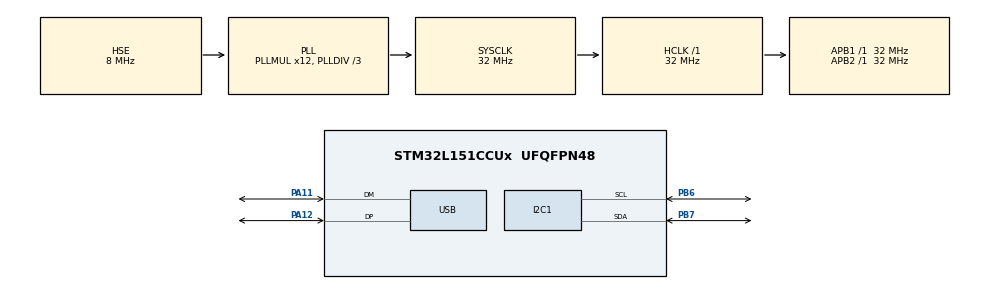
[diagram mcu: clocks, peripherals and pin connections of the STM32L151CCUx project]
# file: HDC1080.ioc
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Mcu.Family=STM32L1
Mcu.Name=STM32L151CCUx
Mcu.Package=UFQFPN48
NVIC.PriorityGroup=NVIC_PRIORITYGROUP_4
NVIC.USB_LP_IRQn=true\:0\:0\:false\:false\:true\:false\:true
PA11.Mode=Device
PA11.Signal=USB_DM
PA12.Mode=Device
PA12.Signal=USB_DP
PA13.Mode=Serial_Wire
PA13.Signal=SYS_JTMS-SWDIO
PA14.Mode=Serial_Wire
PA14.Signal=SYS_JTCK-SWCLK
PB6.Mode=I2C
PB6.Signal=I2C1_SCL
PB7.Mode=I2C
PB7.Signal=I2C1_SDA
PC14-OSC32_IN.Mode=LSE-External-Oscillator
PC14-OSC32_IN.Signal=RCC_OSC32_IN
PC15-OSC32_OUT.Mode=LSE-External-Oscillator
PC15-OSC32_OUT.Signal=RCC_OSC32_OUT
PH0-OSC_IN.Mode=HSE-External-Oscillator
PH0-OSC_IN.Signal=RCC_OSC_IN
PH1-OSC_OUT.Mode=HSE-External-Oscillator
PH1-OSC_OUT.Signal=RCC_OSC_OUT
ProjectManager.HeapSize=0x400
ProjectManager.StackSize=0x800
ProjectManager.TargetToolchain=MDK-ARM V5.27
RCC.48MHZClocksFreq_Value=48000000
RCC.AHBFreq_Value=32000000
RCC.APB1Freq_Value=32000000
RCC.APB1TimFreq_Value=32000000
RCC.APB2Freq_Value=32000000
RCC.APB2TimFreq_Value=32000000
RCC.HCLKFreq_Value=32000000
RCC.HSE_VALUE=8000000
RCC.HSI_VALUE=16000000
RCC.MSI_VALUE=2097000
RCC.PLLDIV=RCC_PLL_DIV3
RCC.PLLMUL=RCC_PLL_MUL12
RCC.SYSCLKFreq_VALUE=32000000
RCC.SYSCLKSource=RCC_SYSCLKSOURCE_PLLCLK
RCC.VCOOutputFreq_Value=96000000
USB_DEVICE.CLASS_NAME_FS=CDC
USB_DEVICE.VirtualMode=Cdc
USB_DEVICE.VirtualModeFS=Cdc_FS
VP_USB_DEVICE_VS_USB_DEVICE_CDC_FS.Mode=CDC_FS
board=custom

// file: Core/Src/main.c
/* USER CODE BEGIN Header */
/**
  ******************************************************************************
  * @file           : main.c
  * @brief          : Main program body
  ******************************************************************************
  * @attention
  *
  * <h2><center>&copy; Copyright (c) 2021 STMicroelectronics.
  * All rights reserved.</center></h2>
  *
  * This software component is licensed by ST under Ultimate Liberty license
  * SLA0044, the "License"; You may not use this file except in compliance with
  * the License. You may obtain a copy of the License at:
  *                             www.st.com/SLA0044
  *
  ******************************************************************************
  */
/* USER CODE END Header */
#include "main.h"
#include "i2c.h"
#include "usb_device.h"
#include "gpio.h"

/* USER CODE BEGIN Includes */
#include "usbd_cdc_if.h"
#include "HDC1080.h"
/* USER CODE END Includes */

void SystemClock_Config(void);

int main(void)
{

  /* MCU Configuration--------------------------------------------------------*/

  /* Reset of all peripherals, Initializes the Flash interface and the Systick. */
  HAL_Init();

  /* USER CODE BEGIN Init */
	uint16_t menuid;
	double temperature =0;

  /* USER CODE END Init */

  /* Configure the system clock */
  SystemClock_Config();

  /* Initialize all configured peripherals */
  MX_GPIO_Init();
  MX_USB_DEVICE_Init();
  MX_I2C1_Init();
  /* USER CODE BEGIN 2 */
	hdc1080_init(HDC1080_RESOLUTION_14BIT, HDC1080_RESOLUTION_14BIT);

  /* USER CODE END 2 */

  /* Infinite loop */
  while (1)
  {

    /* USER CODE BEGIN 3 */
		HAL_Delay(500);

	hdc1080_read_manufacturer_id(&menuid);
	hdc1080_read_temperature(&temperature);
	usb_printf("hello world ID=0x%x  T= %f\r\n",menuid ,temperature);

  }
  /* USER CODE END 3 */
}

void SystemClock_Config(void)
{
  RCC_OscInitTypeDef RCC_OscInitStruct = {0};
  RCC_ClkInitTypeDef RCC_ClkInitStruct = {0};

  /** Configure the main internal regulator output voltage
  */
  __HAL_PWR_VOLTAGESCALING_CONFIG(PWR_REGULATOR_VOLTAGE_SCALE1);
  /** Initializes the RCC Oscillators according to the specified parameters
  * in the RCC_OscInitTypeDef structure.
  */
  RCC_OscInitStruct.OscillatorType = RCC_OSCILLATORTYPE_HSE;
  RCC_OscInitStruct.HSEState = RCC_HSE_ON;
  RCC_OscInitStruct.PLL.PLLState = RCC_PLL_ON;
  RCC_OscInitStruct.PLL.PLLSource = RCC_PLLSOURCE_HSE;
  RCC_OscInitStruct.PLL.PLLMUL = RCC_PLL_MUL12;
  RCC_OscInitStruct.PLL.PLLDIV = RCC_PLL_DIV3;
  if (HAL_RCC_OscConfig(&RCC_OscInitStruct) != HAL_OK)
  {
    Error_Handler();
  }
  /** Initializes the CPU, AHB and APB buses clocks
  */
  RCC_ClkInitStruct.ClockType = RCC_CLOCKTYPE_HCLK|RCC_CLOCKTYPE_SYSCLK
                              |RCC_CLOCKTYPE_PCLK1|RCC_CLOCKTYPE_PCLK2;
  RCC_ClkInitStruct.SYSCLKSource = RCC_SYSCLKSOURCE_PLLCLK;
  RCC_ClkInitStruct.AHBCLKDivider = RCC_SYSCLK_DIV1;
  RCC_ClkInitStruct.APB1CLKDivider = RCC_HCLK_DIV1;
  RCC_ClkInitStruct.APB2CLKDivider = RCC_HCLK_DIV1;

  if (HAL_RCC_ClockConfig(&RCC_ClkInitStruct, FLASH_LATENCY_1) != HAL_OK)
  {
    Error_Handler();
  }
}

void Error_Handler(void)
{
  __disable_irq();
  while (1)
  {
  }
}

/************************ (C) COPYRIGHT STMicroelectronics *****END OF FILE****/
